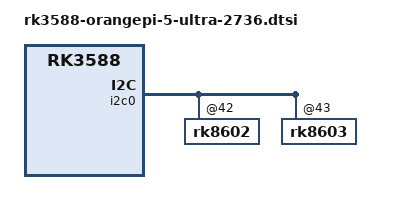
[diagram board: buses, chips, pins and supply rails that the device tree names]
// SPDX-License-Identifier: (GPL-2.0+ OR MIT)
/*
 * PATCHED DTSI – Orange Pi 5 Ultra
 * File: rk3588-orangepi-5-ultra-r08a-lp5-2736.dtsi
 *
 * Revision note:
 * r08a - fixed DTC syntax issue.
 *      - Based on r06 CPU 2.4GHz / 1.05V big-cluster patch.
 *      - DMC OPPs now match the LPDDR5 2736 MHz DDR blob FSP ladder:
 *       534 / 1320 / 1968 / 2736 MHz.
 */


&i2c0 {
	rk8602@42 {
		regulator-max-microvolt = <1050000>;
	};

	rk8603@43 {
		regulator-max-microvolt = <1050000>;
	};
};

&cluster1_opp_table {
	opp-408000000 {
		opp-microvolt = <675000 675000 1050000>,
			       <675000 675000 1050000>;
	};
	opp-600000000 {
		opp-microvolt = <675000 675000 1050000>,
			       <675000 675000 1050000>;
	};
	opp-816000000 {
		opp-microvolt = <675000 675000 1050000>,
			       <675000 675000 1050000>;
	};
	opp-1008000000 {
		opp-microvolt = <675000 675000 1050000>,
			       <675000 675000 1050000>;
	};
	opp-1200000000 {
		opp-microvolt = <675000 675000 1050000>,
			       <675000 675000 1050000>;
	};
	opp-1416000000 {
		opp-microvolt = <725000 725000 1050000>,
			       <725000 725000 1050000>;
		opp-microvolt-L2 = <712500 712500 1050000>,
			       <712500 712500 1050000>;
		opp-microvolt-L3 = <700000 700000 1050000>,
			       <700000 700000 1050000>;
		opp-microvolt-L4 = <700000 700000 1050000>,
			       <700000 700000 1050000>;
		opp-microvolt-L5 = <687500 687500 1050000>,
			       <687500 687500 1050000>;
		opp-microvolt-L6 = <675000 675000 1050000>,
			       <675000 675000 1050000>;
		opp-microvolt-L7 = <675000 675000 1050000>,
			       <675000 675000 1050000>;
	};
	opp-1608000000 {
		opp-microvolt = <762500 762500 1050000>,
			       <762500 762500 1050000>;
		opp-microvolt-L2 = <750000 750000 1050000>,
			       <750000 750000 1050000>;
		opp-microvolt-L3 = <737500 737500 1050000>,
			       <737500 737500 1050000>;
		opp-microvolt-L4 = <725000 725000 1050000>,
			       <725000 725000 1050000>;
		opp-microvolt-L5 = <712500 712500 1050000>,
			       <712500 712500 1050000>;
		opp-microvolt-L6 = <700000 700000 1050000>,
			       <700000 700000 1050000>;
		opp-microvolt-L7 = <700000 700000 1050000>,
			       <700000 700000 1050000>;
	};
	opp-1800000000 {
		opp-microvolt = <850000 850000 1050000>,
			       <850000 850000 1050000>;
		opp-microvolt-L1 = <837500 837500 1050000>,
			       <837500 837500 1050000>;
		opp-microvolt-L2 = <825000 825000 1050000>,
			       <825000 825000 1050000>;
		opp-microvolt-L3 = <812500 812500 1050000>,
			       <812500 812500 1050000>;
		opp-microvolt-L4 = <800000 800000 1050000>,
			       <800000 800000 1050000>;
		opp-microvolt-L5 = <787500 787500 1050000>,
			       <787500 787500 1050000>;
		opp-microvolt-L6 = <775000 775000 1050000>,
			       <775000 775000 1050000>;
		opp-microvolt-L7 = <762500 762500 1050000>,
			       <762500 762500 1050000>;
	};
	opp-2016000000 {
		opp-microvolt = <925000 925000 1050000>,
			       <925000 925000 1050000>;
		opp-microvolt-L1 = <912500 912500 1050000>,
			       <912500 912500 1050000>;
		opp-microvolt-L2 = <900000 900000 1050000>,
			       <900000 900000 1050000>;
		opp-microvolt-L3 = <887500 887500 1050000>,
			       <887500 887500 1050000>;
		opp-microvolt-L4 = <875000 875000 1050000>,
			       <875000 875000 1050000>;
		opp-microvolt-L5 = <862500 862500 1050000>,
			       <862500 862500 1050000>;
		opp-microvolt-L6 = <850000 850000 1050000>,
			       <850000 850000 1050000>;
		opp-microvolt-L7 = <837500 837500 1050000>,
			       <837500 837500 1050000>;
	};
	opp-2208000000 {
		opp-microvolt = <987500 987500 1050000>,
			       <987500 987500 1050000>;
		opp-microvolt-L1 = <975000 975000 1050000>,
			       <975000 975000 1050000>;
		opp-microvolt-L2 = <962500 962500 1050000>,
			       <962500 962500 1050000>;
		opp-microvolt-L3 = <950000 950000 1050000>,
			       <950000 950000 1050000>;
		opp-microvolt-L4 = <962500 962500 1050000>,
			       <962500 962500 1050000>;
		opp-microvolt-L5 = <950000 950000 1050000>,
			       <950000 950000 1050000>;
		opp-microvolt-L6 = <925000 925000 1050000>,
			       <925000 925000 1050000>;
		opp-microvolt-L7 = <912500 912500 1050000>,
			       <912500 912500 1050000>;
	};
	opp-2256000000 {
		opp-microvolt = <1000000 1000000 1050000>,
			       <1000000 1000000 1050000>;
	};
	opp-2304000000 {
		opp-microvolt = <1000000 1000000 1050000>,
			       <1000000 1000000 1050000>;
	};
	opp-2352000000 {
		opp-microvolt = <1000000 1000000 1050000>,
			       <1000000 1000000 1050000>;
	};
	opp-2400000000 {
		opp-supported-hw = <0xe9 0x48>;
		opp-microvolt = <1050000 1050000 1050000>,
			       <1050000 1050000 1050000>;
	};
};

&cluster2_opp_table {
	opp-408000000 {
		opp-microvolt = <675000 675000 1050000>,
			       <675000 675000 1050000>;
	};
	opp-600000000 {
		opp-microvolt = <675000 675000 1050000>,
			       <675000 675000 1050000>;
	};
	opp-816000000 {
		opp-microvolt = <675000 675000 1050000>,
			       <675000 675000 1050000>;
	};
	opp-1008000000 {
		opp-microvolt = <675000 675000 1050000>,
			       <675000 675000 1050000>;
	};
	opp-1200000000 {
		opp-microvolt = <675000 675000 1050000>,
			       <675000 675000 1050000>;
	};
	opp-1416000000 {
		opp-microvolt = <725000 725000 1050000>,
			       <725000 725000 1050000>;
		opp-microvolt-L2 = <712500 712500 1050000>,
			       <712500 712500 1050000>;
		opp-microvolt-L3 = <700000 700000 1050000>,
			       <700000 700000 1050000>;
		opp-microvolt-L4 = <700000 700000 1050000>,
			       <700000 700000 1050000>;
		opp-microvolt-L5 = <687500 687500 1050000>,
			       <687500 687500 1050000>;
		opp-microvolt-L6 = <675000 675000 1050000>,
			       <675000 675000 1050000>;
		opp-microvolt-L7 = <675000 675000 1050000>,
			       <675000 675000 1050000>;
	};
	opp-1608000000 {
		opp-microvolt = <762500 762500 1050000>,
			       <762500 762500 1050000>;
		opp-microvolt-L2 = <750000 750000 1050000>,
			       <750000 750000 1050000>;
		opp-microvolt-L3 = <737500 737500 1050000>,
			       <737500 737500 1050000>;
		opp-microvolt-L4 = <725000 725000 1050000>,
			       <725000 725000 1050000>;
		opp-microvolt-L5 = <712500 712500 1050000>,
			       <712500 712500 1050000>;
		opp-microvolt-L6 = <700000 700000 1050000>,
			       <700000 700000 1050000>;
		opp-microvolt-L7 = <700000 700000 1050000>,
			       <700000 700000 1050000>;
	};
	opp-1800000000 {
		opp-microvolt = <850000 850000 1050000>,
			       <850000 850000 1050000>;
		opp-microvolt-L1 = <837500 837500 1050000>,
			       <837500 837500 1050000>;
		opp-microvolt-L2 = <825000 825000 1050000>,
			       <825000 825000 1050000>;
		opp-microvolt-L3 = <812500 812500 1050000>,
			       <812500 812500 1050000>;
		opp-microvolt-L4 = <800000 800000 1050000>,
			       <800000 800000 1050000>;
		opp-microvolt-L5 = <787500 787500 1050000>,
			       <787500 787500 1050000>;
		opp-microvolt-L6 = <775000 775000 1050000>,
			       <775000 775000 1050000>;
		opp-microvolt-L7 = <762500 762500 1050000>,
			       <762500 762500 1050000>;
	};
	opp-2016000000 {
		opp-microvolt = <925000 925000 1050000>,
			       <925000 925000 1050000>;
		opp-microvolt-L1 = <912500 912500 1050000>,
			       <912500 912500 1050000>;
		opp-microvolt-L2 = <900000 900000 1050000>,
			       <900000 900000 1050000>;
		opp-microvolt-L3 = <887500 887500 1050000>,
			       <887500 887500 1050000>;
		opp-microvolt-L4 = <875000 875000 1050000>,
			       <875000 875000 1050000>;
		opp-microvolt-L5 = <862500 862500 1050000>,
			       <862500 862500 1050000>;
		opp-microvolt-L6 = <850000 850000 1050000>,
			       <850000 850000 1050000>;
		opp-microvolt-L7 = <837500 837500 1050000>,
			       <837500 837500 1050000>;
	};
	opp-2208000000 {
		opp-microvolt = <987500 987500 1050000>,
			       <987500 987500 1050000>;
		opp-microvolt-L3 = <975000 975000 1050000>,
			       <975000 975000 1050000>;
		opp-microvolt-L4 = <962500 962500 1050000>,
			       <962500 962500 1050000>;
		opp-microvolt-L5 = <950000 950000 1050000>,
			       <950000 950000 1050000>;
		opp-microvolt-L6 = <925000 925000 1050000>,
			       <925000 925000 1050000>;
		opp-microvolt-L7 = <912500 912500 1050000>,
			       <912500 912500 1050000>;
	};
	opp-2256000000 {
		opp-microvolt = <1000000 1000000 1050000>,
			       <1000000 1000000 1050000>;
	};
	opp-2304000000 {
		opp-microvolt = <1000000 1000000 1050000>,
			       <1000000 1000000 1050000>;
	};
	opp-2352000000 {
		opp-microvolt = <1000000 1000000 1050000>,
			       <1000000 1000000 1050000>;
	};
	opp-2400000000 {
		opp-supported-hw = <0xe9 0x48>;
		opp-microvolt = <1050000 1050000 1050000>,
			       <1050000 1050000 1050000>;
	};
};

/* Exact DMC OPPs for the selected LPDDR5 DDR blob FSP ladder. */
&dmc_opp_table {
	/delete-node/ opp-528000000;
	/delete-node/ opp-1068000000;
	/delete-node/ opp-1560000000;
	/delete-node/ opp-2750000000;

		opp-534000000 {
			opp-supported-hw = <0xf9 0xffff>;
			opp-hz = /bits/ 64 <534000000>;
			opp-microvolt = <675000 675000 875000>,
					<725000 725000 800000>;
			opp-microvolt-L1 = <675000 675000 875000>,
					   <700000 700000 800000>;
			opp-microvolt-L2 = <675000 675000 875000>,
					   <687500 687500 800000>;
			opp-microvolt-L3 = <675000 675000 875000>,
					   <675000 675000 800000>;
		};

		opp-1320000000 {
			opp-supported-hw = <0xf9 0xffff>;
			opp-hz = /bits/ 64 <1320000000>;
			opp-microvolt = <800000 800000 875000>,
					<750000 750000 800000>;
			opp-microvolt-L1 = <775000 775000 875000>,
					   <725000 725000 800000>;
			opp-microvolt-L2 = <750000 750000 875000>,
					   <712500 712500 800000>;
			opp-microvolt-L3 = <725000 725000 875000>,
					   <700000 700000 800000>;
		};

		opp-1968000000 {
			opp-supported-hw = <0xe9 0xffff>;
			opp-hz = /bits/ 64 <1968000000>;
			opp-microvolt = <875000 875000 875000>,
					<750000 750000 800000>;
			opp-microvolt-L1 = <850000 850000 875000>,
					   <750000 750000 800000>;
			opp-microvolt-L2 = <837500 837500 875000>,
					   <725000 725000 800000>;
			opp-microvolt-L3 = <825000 820000 875000>,
					   <700000 700000 800000>;
		};

		opp-2736000000 {
			opp-supported-hw = <0xe9 0xffff>;
			opp-hz = /bits/ 64 <2736000000>;
			opp-microvolt = <875000 875000 875000>,
					<750000 750000 800000>;
			opp-microvolt-L1 = <850000 850000 875000>,
					   <750000 750000 800000>;
			opp-microvolt-L2 = <837500 837500 875000>,
					   <725000 725000 800000>;
			opp-microvolt-L3 = <825000 820000 875000>,
					   <700000 700000 800000>;
		};
};
